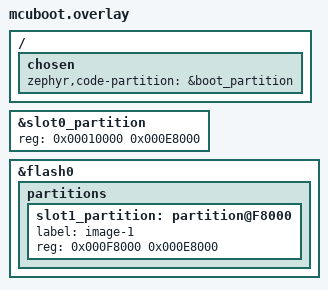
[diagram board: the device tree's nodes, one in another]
/*
 * MCUboot DTS overlay — bootloader runs from boot_partition (0x0),
 * not slot0_partition.  Without the code-partition chosen, FLASH_LOAD_OFFSET
 * = 0x10000 and the bootloader is linked at the wrong address.
 *
 * Also resizes slot0/slot1 to 928 KB (from the 800 KB default in rt583.dtsi)
 * so a single bootloader image works for both Matter lighting-app (~866 KB)
 * and the smaller apps.  Apps that fit in 800 KB still flash fine — MCUboot
 * only requires that the image header fits within slot0.
 *
 * Layout (2 MB flash):
 *   0x000000 – 0x010000  boot_partition    64 KB  MCUboot
 *   0x010000 – 0x0F8000  slot0_partition  928 KB  primary app
 *   0x0F8000 – 0x1E0000  slot1_partition  928 KB  OTA / Direct-XIP failover
 *   0x1E0000 – 0x1F0000  storage_partition 64 KB  settings / NVS
 *   0x1F0000 – 0x200000  factory_partition 64 KB  factory data
 *
 * Note: staging_partition is removed — OTA flows that need it must build
 * with an app-side overlay that re-adds it in a different location.
 */

/ {
	chosen {
		zephyr,code-partition = &boot_partition;
	};
};

&slot0_partition {
	reg = <0x00010000 0x000E8000>;  /* 928 KB */
};

/*
 * Relocate slot1 to 0xF8000 (right after the enlarged slot0).
 * Delete the old node and recreate it so unit-address matches reg (avoids
 * dtc warnings).
 */
/delete-node/ &slot1_partition;

&flash0 {
	partitions {
		slot1_partition: partition@F8000 {
			label = "image-1";
			reg = <0x000F8000 0x000E8000>;  /* 928 KB — equal to slot0, required by MCUboot */
		};
	};
};

/* staging overlaps with the enlarged slot1 — remove it. */
/delete-node/ &staging_partition;
